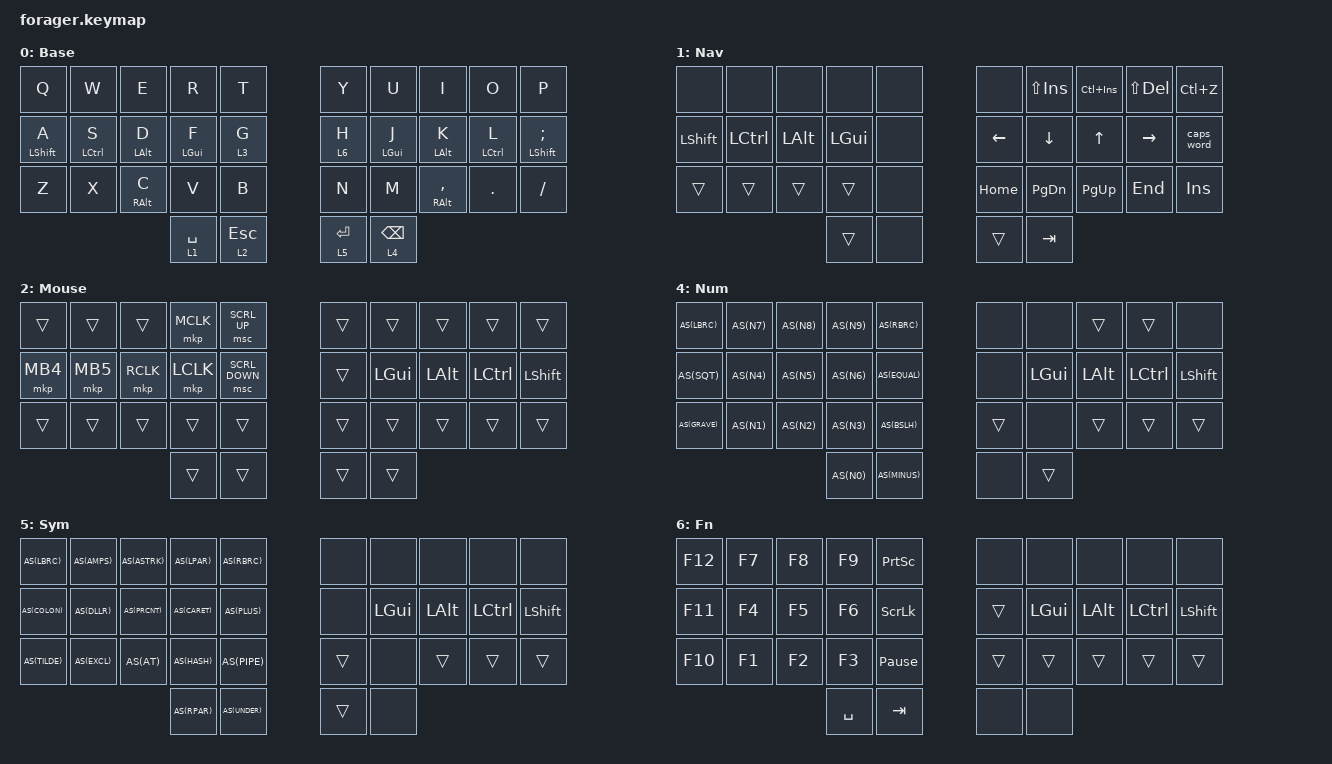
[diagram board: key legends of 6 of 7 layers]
/*
 * Forager (34 keys) - translation of keyruu's QMK Voyager layout
 * (Oryx oyYzP/WvRL5z, Miryoku-shaped).
 *
 * Positions: 0-4 top row, 5-9 top row right, 10-19 home row, 20-29 bottom row,
 * 30-33 thumbs (30/31 left outer/inner, 32/33 right inner/outer).
 *
 * Layer numbers are the Voyager's: 1 nav, 2 mouse, 3 media, 4 numbers,
 * 5 symbols, 6 functions.
 *
 * The Forager has no trackball and only the XIAO's single status LED, so the
 * Voyager's trackball keys became plain mouse keys and its RGB keys became the
 * rgbled-widget status behaviors (battery/connection/layer). Numbers and
 * symbols keep auto-shift, i.e. hold for the shifted variant.
 */

#include <behaviors.dtsi>
#include <behaviors/rgbled_widget.dtsi>
#include <dt-bindings/zmk/keys.h>
#include <dt-bindings/zmk/bt.h>
#include <dt-bindings/zmk/pointing.h>

#define AS(keycode) &as LS(keycode) keycode

/ {
    behaviors {
        as: auto_shift {
            compatible = "zmk,behavior-hold-tap";
            #binding-cells = <2>;
            tapping-term-ms = <250>;
            require-prior-idle-ms = <100>;
            flavor = "tap-preferred";
            bindings = <&kp>, <&kp>;
        };

        // Home-row mods only resolve when the other hand (or a thumb) taps,
        // so fast rolling on one hand stays letters.
        hml: home_row_mods_left {
            compatible = "zmk,behavior-hold-tap";
            #binding-cells = <2>;
            flavor = "balanced";
            tapping-term-ms = <280>;
            quick-tap-ms = <175>;
            require-prior-idle-ms = <150>;
            bindings = <&kp>, <&kp>;
            hold-trigger-key-positions = <5 6 7 8 9 15 16 17 18 19 25 26 27 28 29 30 31 32 33>;
            // Check the position on release, so same-hand mods (e.g. S+D) can stack.
            hold-trigger-on-release;
        };

        hmr: home_row_mods_right {
            compatible = "zmk,behavior-hold-tap";
            #binding-cells = <2>;
            flavor = "balanced";
            tapping-term-ms = <280>;
            quick-tap-ms = <175>;
            require-prior-idle-ms = <150>;
            bindings = <&kp>, <&kp>;
            hold-trigger-key-positions = <0 1 2 3 4 10 11 12 13 14 20 21 22 23 24 30 31 32 33>;
            // Check the position on release, so same-hand mods (e.g. L+;) can stack.
            hold-trigger-on-release;
        };
    };

    combos {
        compatible = "zmk,combos";

        // Voyager: Esc+Bspc -> Del, Space+Enter -> Tab (one thumb per half).
        thumb_delete {
            timeout-ms = <50>;
            key-positions = <31 33>;
            bindings = <&kp DEL>;
        };

        thumb_tab {
            timeout-ms = <50>;
            key-positions = <30 32>;
            bindings = <&kp TAB>;
        };
    };

    keymap {
        compatible = "zmk,keymap";

        base {
            display-name = "Base";
            bindings = <
&kp Q           &kp W           &kp E           &kp R           &kp T               &kp Y           &kp U           &kp I              &kp O              &kp P
&hml LSHIFT A   &hml LCTRL S    &hml LALT D     &hml LGUI F     &lt 3 G             &lt 6 H         &hmr LGUI J     &hmr LALT K        &hmr LCTRL L       &hmr LSHIFT SEMI
&kp Z           &kp X           &hml RALT C     &kp V           &kp B               &kp N           &kp M           &hmr RALT COMMA    &kp DOT            &kp FSLH
                                                &lt 1 SPACE     &lt 2 ESC                                           &lt 5 ENTER        &lt 4 BSPC
            >;
        };

        nav {
            display-name = "Nav";
            bindings = <
&none           &none           &none           &none           &none               &none           &kp LS(INS)     &kp LC(INS)        &kp LS(DEL)        &kp LC(Z)
&kp LSHIFT      &kp LCTRL       &kp LALT        &kp LGUI        &none               &kp LEFT        &kp DOWN        &kp UP             &kp RIGHT          &caps_word
&trans          &trans          &trans          &trans          &none               &kp HOME        &kp PG_DN       &kp PG_UP          &kp END            &kp INS
                                                &trans          &none                                              &trans             &kp TAB
            >;
        };

        mouse {
            display-name = "Mouse";
            bindings = <
&trans          &trans          &trans          &mkp MCLK       &msc SCRL_UP        &trans          &trans          &trans             &trans             &trans
&mkp MB4        &mkp MB5        &mkp RCLK       &mkp LCLK       &msc SCRL_DOWN      &trans          &kp LGUI        &kp LALT           &kp LCTRL          &kp LSHIFT
&trans          &trans          &trans          &trans          &trans              &trans          &trans          &trans             &trans             &trans
                                                &trans          &trans                                             &trans             &trans
            >;
        };

        media {
            display-name = "Media";
            bindings = <
&none           &none           &none           &none           &none               &ind_bat        &ind_con        &ind_lyr           &studio_unlock     &bootloader
&kp LSHIFT      &kp LCTRL       &kp LALT        &kp LGUI        &trans              &kp C_PREV      &kp C_VOL_DN    &kp C_MUTE         &kp C_VOL_UP       &kp C_NEXT
&bt BT_SEL 0    &bt BT_SEL 1    &bt BT_SEL 2    &bt BT_SEL 3    &bt BT_SEL 4        &kp LA(LS(SPACE)) &kp LA(LS(J)) &kp LA(LS(K))      &kp LA(LS(N))      &kp LA(LC(LS(L)))
                                                &none           &bt BT_CLR                                         &kp C_STOP         &kp C_PP
            >;
        };

        num {
            display-name = "Num";
            bindings = <
AS(LBRC)        AS(N7)          AS(N8)          AS(N9)          AS(RBRC)            &none           &none           &trans             &trans             &none
AS(SQT)         AS(N4)          AS(N5)          AS(N6)          AS(EQUAL)           &none           &kp LGUI        &kp LALT           &kp LCTRL          &kp LSHIFT
AS(GRAVE)       AS(N1)          AS(N2)          AS(N3)          AS(BSLH)            &trans          &none           &trans             &trans             &trans
                                                AS(N0)          AS(MINUS)                                          &none              &trans
            >;
        };

        sym {
            display-name = "Sym";
            bindings = <
AS(LBRC)        AS(AMPS)        AS(ASTRK)       AS(LPAR)        AS(RBRC)            &none           &none           &none              &none              &none
AS(COLON)       AS(DLLR)        AS(PRCNT)       AS(CARET)       AS(PLUS)            &none           &kp LGUI        &kp LALT           &kp LCTRL          &kp LSHIFT
AS(TILDE)       AS(EXCL)        AS(AT)          AS(HASH)        AS(PIPE)            &trans          &none           &trans             &trans             &trans
                                                AS(RPAR)        AS(UNDER)                                          &trans             &none
            >;
        };

        fn {
            display-name = "Fn";
            bindings = <
&kp F12         &kp F7          &kp F8          &kp F9          &kp PSCRN           &none           &none           &none              &none              &none
&kp F11         &kp F4          &kp F5          &kp F6          &kp SLCK            &trans          &kp LGUI        &kp LALT           &kp LCTRL          &kp LSHIFT
&kp F10         &kp F1          &kp F2          &kp F3          &kp PAUSE_BREAK     &trans          &trans          &trans             &trans             &trans
                                                &kp SPACE       &kp TAB                                            &none              &none
            >;
        };
    };
};

// Voyager used QMK's 200ms tapping term for layer taps.
&lt {
    tapping-term-ms = <200>;
    quick-tap-ms = <200>;
};
